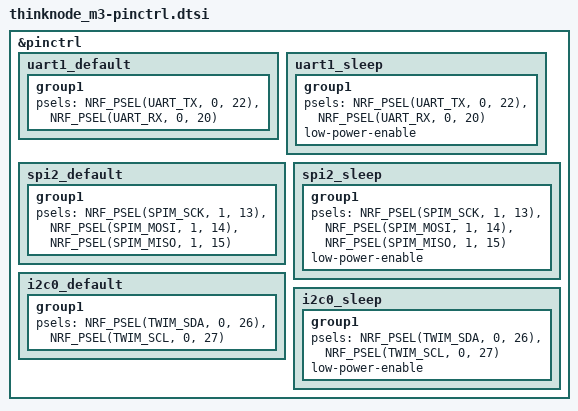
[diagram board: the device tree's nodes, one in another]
/*
 * SPDX-License-Identifier: GPL-3.0-or-later
 * SPDX-FileCopyrightText: The contributors to the LICHEN project
 *
 * Elecrow ThinkNode M3 pin assignments.
 *
 * All assignments verified against Meshtastic firmware:
 *   variants/nrf52840/ELECROW-ThinkNode-M3/variant.h
 */

&pinctrl {
	/*
	 * UART1: GPS
	 *   TX = P0.22  RX = P0.20
	 */
	uart1_default: uart1_default {
		group1 {
			psels = <NRF_PSEL(UART_TX, 0, 22)>,
				<NRF_PSEL(UART_RX, 0, 20)>;
		};
	};
	uart1_sleep: uart1_sleep {
		group1 {
			psels = <NRF_PSEL(UART_TX, 0, 22)>,
				<NRF_PSEL(UART_RX, 0, 20)>;
			low-power-enable;
		};
	};

	/*
	 * SPI2: LR1110 radio
	 *   SCK  = P1.13  MOSI = P1.14  MISO = P1.15  CS = P1.12
	 */
	spi2_default: spi2_default {
		group1 {
			psels = <NRF_PSEL(SPIM_SCK,  1, 13)>,
				<NRF_PSEL(SPIM_MOSI, 1, 14)>,
				<NRF_PSEL(SPIM_MISO, 1, 15)>;
		};
	};
	spi2_sleep: spi2_sleep {
		group1 {
			psels = <NRF_PSEL(SPIM_SCK,  1, 13)>,
				<NRF_PSEL(SPIM_MOSI, 1, 14)>,
				<NRF_PSEL(SPIM_MISO, 1, 15)>;
			low-power-enable;
		};
	};

	/*
	 * I2C0: PCF8563 RTC, sensors
	 *   SDA = P0.26  SCL = P0.27
	 */
	i2c0_default: i2c0_default {
		group1 {
			psels = <NRF_PSEL(TWIM_SDA, 0, 26)>,
				<NRF_PSEL(TWIM_SCL, 0, 27)>;
		};
	};
	i2c0_sleep: i2c0_sleep {
		group1 {
			psels = <NRF_PSEL(TWIM_SDA, 0, 26)>,
				<NRF_PSEL(TWIM_SCL, 0, 27)>;
			low-power-enable;
		};
	};
};
